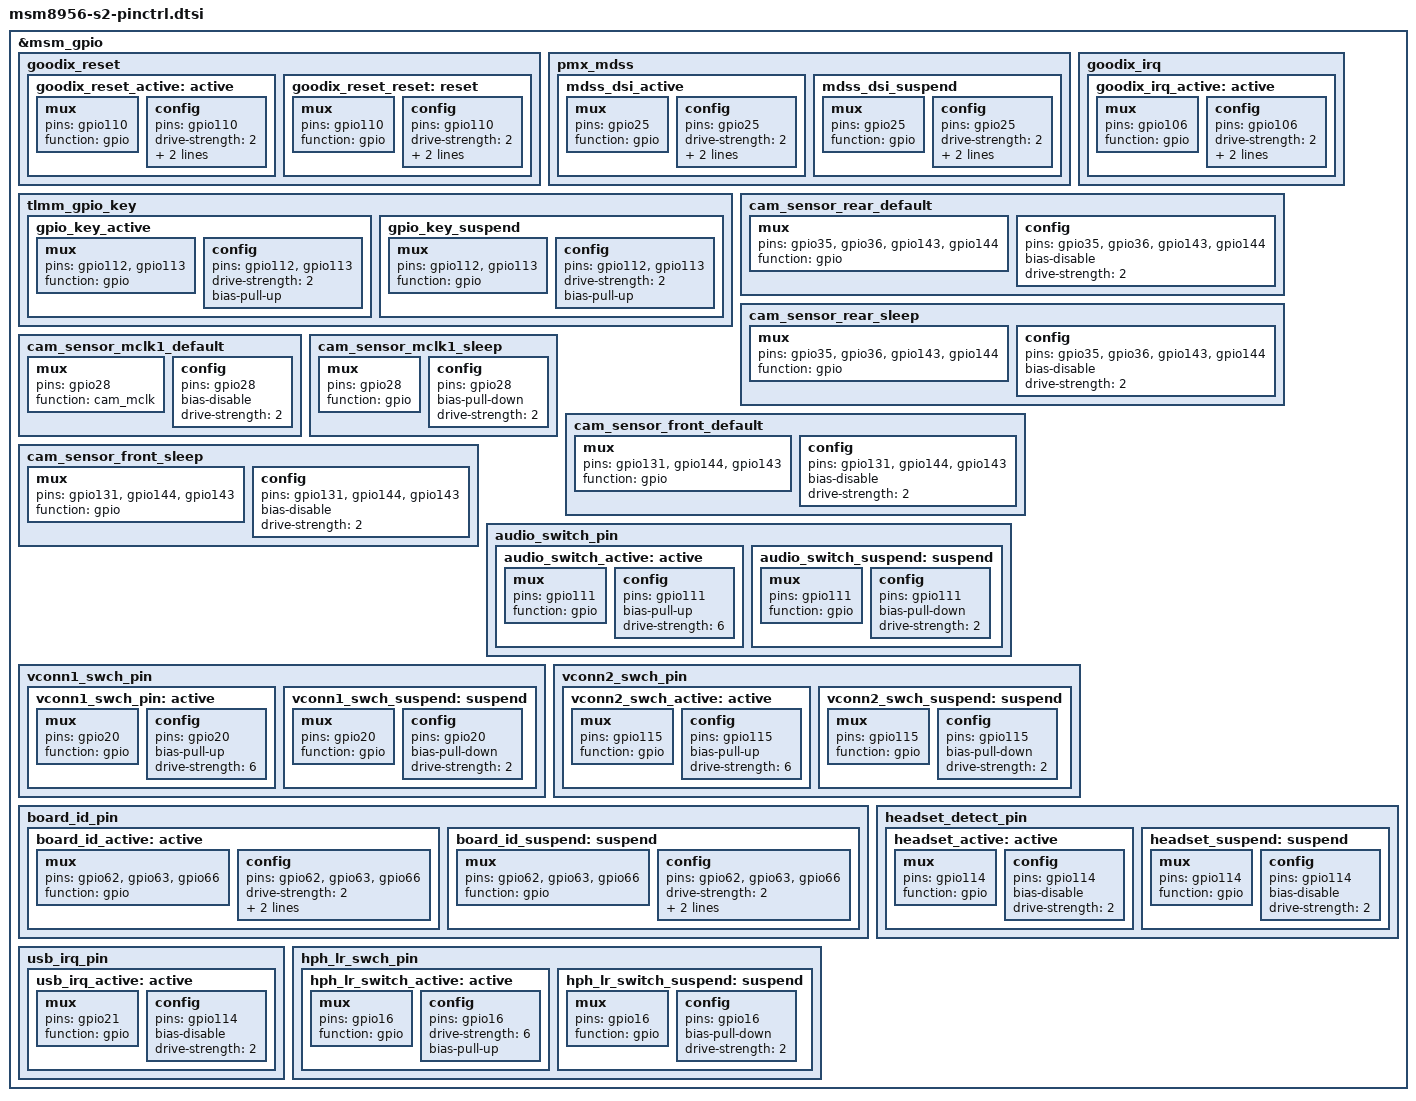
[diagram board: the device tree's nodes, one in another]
&msm_gpio{
/delete-node/  cdc-reset-line;
 /delete-node/ pmx_sdc3_clk;
/delete-node/  pmx_sdc3_cmd;
/delete-node/ pmx_sdc3_data;
	goodix_reset: goodix_reset {
			goodix_reset_active: active {
				mux {
					pins = "gpio110";
					function = "gpio";
				};
				config {
					pins = "gpio110";
					drive-strength = <2>;
					bias-disable;
					output-high;
				};
			};

			goodix_reset_reset: reset {
				mux {
					pins = "gpio110";
					function = "gpio";
				};
				config {
					pins = "gpio110";
					drive-strength = <2>;
					bias-disable;
					output-low;
				};
			};
	};



	pmx_mdss: pmx_mdss {
			mdss_dsi_active: mdss_dsi_active {
				mux {
					pins = "gpio25";
					function = "gpio";
				};

				config {
					pins = "gpio25";
					drive-strength = <2>; /* 8 mA */
					bias-disable = <0>; /* no pull */
					output-high;
				};
			};

			mdss_dsi_suspend: mdss_dsi_suspend {
				mux {
					pins = "gpio25";
					function = "gpio";
				};

				config {
					pins = "gpio25";
					drive-strength = <2>; /* 2 mA */
					bias-pull-down; /* pull down */
					output-low;
				};
			};
		};

	goodix_irq: goodix_irq  {
			goodix_irq_active: active {
				mux {
					pins = "gpio106";
					function = "gpio";
				};
				config {
					pins = "gpio106";
					drive-strength = <2>;
					bias-disable;
					input-enable;
				};
			};

	};



tlmm_gpio_key {
			gpio_key_active: gpio_key_active {
				mux {
					pins = "gpio112", "gpio113";
					function = "gpio";
				};

				config {
					pins = "gpio112", "gpio113";
					drive-strength = <2>;
					bias-pull-up;
				};
			};

			gpio_key_suspend: gpio_key_suspend {
				mux {
				pins = "gpio112", "gpio113";
					function = "gpio";
				};

				config {
					pins = "gpio112", "gpio113";
					drive-strength = <2>;
					bias-pull-up;
				};
			};
		};



	cam_sensor_rear_default: cam_sensor_rear_default {
			/* RESET, STANDBY */
			mux {
				pins = "gpio35", "gpio36", "gpio143", "gpio144";
				function = "gpio";
			};

			config {
				pins = "gpio35", "gpio36", "gpio143", "gpio144";
				bias-disable; /* No PULL */
				drive-strength = <2>; /* 2 MA */
			};
		};

	cam_sensor_rear_sleep: cam_sensor_rear_sleep {
			/* RESET, STANDBY */
			mux {
				pins = "gpio35", "gpio36", "gpio143", "gpio144";
				function = "gpio";
			};

			config {
				pins = "gpio35", "gpio36", "gpio143", "gpio144";
				bias-disable; /* No PULL */
				drive-strength = <2>; /* 2 MA */
			};
		};

		/delete-node/ cam_sensor_rear_vana;

		/delete-node/ cam_sensor_rear_vana_sleep;

		cam_sensor_mclk1_default: cam_sensor_mclk1_default {
			/* MCLK1 */
			mux {
				/* CLK, DATA */
				pins = "gpio28";
				function = "cam_mclk";
			};

			config {
				pins = "gpio28";
				bias-disable; /* No PULL */
				drive-strength = <2>; /* 2 MA */
			};
		};

		cam_sensor_mclk1_sleep: cam_sensor_mclk1_sleep {
			/* MCLK1 */
			mux {
				/* CLK, DATA */
				pins = "gpio28";
				function = "gpio";
			};

			config {
				pins = "gpio28";
				bias-pull-down; /* PULL DOWN */
				drive-strength = <2>; /* 2 MA */
			};
		};

		cam_sensor_front_default: cam_sensor_front_default {
			/* RESET, STANDBY */
			mux {
				pins = "gpio131", "gpio144", "gpio143";
				function = "gpio";
			};

			config {
				pins = "gpio131", "gpio144", "gpio143";
				bias-disable; /* No PULL */
				drive-strength = <2>; /* 2 MA */
			};
		};

		cam_sensor_front_sleep: cam_sensor_front_sleep {
			/* RESET, STANDBY */
			mux {
				pins = "gpio131", "gpio144", "gpio143";
				function = "gpio";
			};

			config {
				pins = "gpio131", "gpio144", "gpio143";
				bias-disable; /* No PULL */
				drive-strength = <2>; /* 2 MA */
			};
		};
		/delete-node/  cam_sensor_front_vdig;
		/delete-node/  cam_sensor_front_vdig_sleep;
		 /delete-node/ cam_sensor_mclk2_default;
		 /delete-node/ cam_sensor_mclk2_sleep;
		 /delete-node/ cam_sensor_front1_default;
		/delete-node/ cam_sensor_front1_sleep;

///////////////////////////////////////////////////////////////////

audio_switch_pin: audio_switch_pin {

	audio_switch_active:active{
			/* RESET, STANDBY */
			mux {
				pins = "gpio111";
				function = "gpio";
			};

			config {
				pins = "gpio111";
				bias-pull-up;
				drive-strength = <6>; /* 2 MA */
			};
		};
	audio_switch_suspend: suspend{
			/* RESET, STANDBY */
			mux {
				pins = "gpio111";
				function = "gpio";
			};

			config {
				pins = "gpio111";
				bias-pull-down;
				drive-strength = <2>; /* 2 MA */
			};
		};

	};
//////////////////////////////////////////////////////////////////



vconn1_swch_pin: vconn1_swch_pin {

	vconn1_swch_pin:active{
			
			mux {
				pins = "gpio20";
				function = "gpio";
			};

			config {
				pins = "gpio20";
				bias-pull-up;
				drive-strength = <6>; /* 2 MA */
			};
		};
	vconn1_swch_suspend: suspend{
			
			mux {
				pins = "gpio20";
				function = "gpio";
			};

			config {
				pins = "gpio20";
				bias-pull-down;
				drive-strength = <2>; /* 2 MA */
			};
		};

	};

/////////////////////////////////////////////////////////////////



vconn2_swch_pin: vconn2_swch_pin {

	vconn2_swch_active: active{
			
			mux {
				pins = "gpio115";
				function = "gpio";
			};

			config {
				pins = "gpio115";
				bias-pull-up;
				drive-strength = <6>; /* 2 MA */
			};
		};
	vconn2_swch_suspend: suspend{
			
			mux {
				pins = "gpio115";
				function = "gpio";
			};

			config {
				pins = "gpio115";
				bias-pull-down;
				drive-strength = <2>; /* 2 MA */
			};
		};

	};


//////////////////////////////////////////////////////////////////////////

board_id_pin: board_id_pin {

	board_id_active: active{
			
			mux {
				pins = "gpio62","gpio63","gpio66";
				function = "gpio";
			};

			config {
				pins = "gpio62","gpio63","gpio66";
				drive-strength = <2>;
				input-enable;
				bias-pull-up;
			};
		};
	board_id_suspend: suspend{
			
			mux {
				pins = "gpio62","gpio63","gpio66";
				function = "gpio";
			};

			config {
				pins = "gpio62","gpio63","gpio66";
				drive-strength = <2>;
				input-enable;
				bias-pull-down;
			};
		};

	};
//////////////////////////////////////////////////////////////////////////



headset_detect_pin: headset_detect_pin {

	headset_active: active{
			
			mux {
				pins = "gpio114";
				function = "gpio";
			};

			config {
				pins = "gpio114";
				bias-disable;
				drive-strength = <2>; /* 2 MA */
			};
		};
	headset_suspend: suspend {
			
			mux {
				pins = "gpio114";
				function = "gpio";
			};

			config {
				pins = "gpio114";
				bias-disable;
				drive-strength = <2>; /* 2 MA */
			};
		};

	};



/////////////////////////////////////////////////////////////////////////////


usb_irq_pin: usb_irq_pin {

	usb_irq_active: active{
			
			mux {
				pins = "gpio21";
				function = "gpio";
			};

			config {
				pins = "gpio114";
				bias-disable;
				drive-strength = <2>; /* 2 MA */
			};
		};
	
	};


///////////////////////////////////////////////////////////


hph_lr_swch_pin: hph_lr_swch_pin {

	hph_lr_switch_active: active{
			
			mux {
				pins = "gpio16";
				function = "gpio";
			};

			config {
				pins = "gpio16";
				drive-strength = <6>;
				bias-pull-up;
			};
		};
	hph_lr_switch_suspend: suspend{
			
			mux {
				pins = "gpio16";
				function = "gpio";
			};

			config {
				pins = "gpio16";
				bias-pull-down;
				drive-strength = <2>; /* 2 MA */
			};
		};

	};


/////////////////////////////////////
/delete-node/  pmx_rd_nfc_int;

/delete-node/  pmx_nfc_reset;












};
